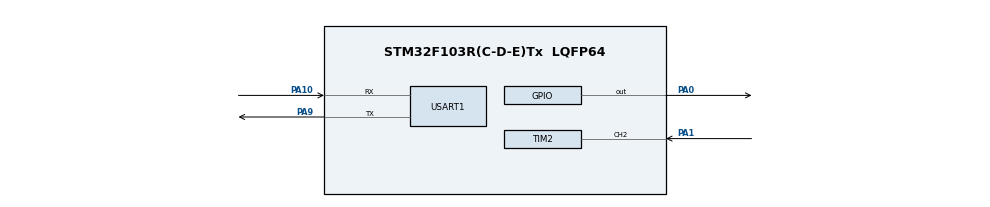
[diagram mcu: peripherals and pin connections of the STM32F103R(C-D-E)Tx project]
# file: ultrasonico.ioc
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Mcu.Family=STM32F1
Mcu.Name=STM32F103R(C-D-E)Tx
Mcu.Package=LQFP64
NVIC.PriorityGroup=NVIC_PRIORITYGROUP_4
PA0-WKUP.Signal=GPIO_Output
PA1.Signal=S_TIM2_CH2
PA10.Mode=Asynchronous
PA10.Signal=USART1_RX
PA9.Mode=Asynchronous
PA9.Signal=USART1_TX
ProjectManager.HeapSize=0x200
ProjectManager.StackSize=0x400
ProjectManager.TargetToolchain=STM32CubeIDE
RCC.APB1Freq_Value=8000000
RCC.APB2Freq_Value=8000000
SH.S_TIM2_CH2.0=TIM2_CH2,Input_Capture2_from_TI2
TIM2.Channel-Input_Capture2_from_TI2=TIM_CHANNEL_2
TIM2.ICPrescaler-Input_Capture2_from_TI2=TIM_ICPSC_DIV1
TIM2.Prescaler=71
USART1.VirtualMode=VM_ASYNC
VP_SYS_VS_ND.Mode=No_Debug
board=custom

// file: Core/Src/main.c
/* USER CODE BEGIN Header */
/**
  ******************************************************************************
  * @file           : main.c
  * @brief          : Main program body
  ******************************************************************************
  */
/* USER CODE END Header */

#include "main.h"

/* USER CODE BEGIN Includes */
#include "ultrasonic.h"
#include <stdio.h>
/* USER CODE END Includes */

UART_HandleTypeDef huart1;
TIM_HandleTypeDef htim2;

/* USER CODE BEGIN PV */
uint32_t distancia_cm = 0;
/* USER CODE END PV */

void SystemClock_Config(void);
static void MX_GPIO_Init(void);
static void MX_TIM2_Init(void);
static void MX_USART1_UART_Init(void);

/* USER CODE BEGIN 0 */
int __io_putchar(int ch)
{
    HAL_UART_Transmit(&huart1, (uint8_t *)&ch, 1, HAL_MAX_DELAY);
    return ch;
}
/* USER CODE END 0 */

int main(void)
{
    HAL_Init();
    SystemClock_Config();
    MX_GPIO_Init();
    MX_TIM2_Init();
    MX_USART1_UART_Init();

    /* USER CODE BEGIN 2 */
    HAL_TIM_Base_Start(&htim2, TIM_CHANNEL_2);
    /* USER CODE END 2 */

    while (1)
    {
        /* USER CODE BEGIN 3 */
        distancia_cm = Ultrasonic_GetDistance_cm();
        printf("Distancia: %lu cm\r\n", distancia_cm);
        HAL_Delay(200);
        /* USER CODE END 3 */
    }
}

void SystemClock_Config(void)
{
    RCC_OscInitTypeDef RCC_OscInitStruct = {0};
    RCC_ClkInitTypeDef RCC_ClkInitStruct = {0};

    RCC_OscInitStruct.OscillatorType = RCC_OSCILLATORTYPE_HSI;
    RCC_OscInitStruct.HSIState = RCC_HSI_ON;
    RCC_OscInitStruct.HSICalibrationValue = RCC_HSICALIBRATION_DEFAULT;
    RCC_OscInitStruct.PLL.PLLState = RCC_PLL_NONE;
    if (HAL_RCC_OscConfig(&RCC_OscInitStruct) != HAL_OK)
        Error_Handler();

    RCC_ClkInitStruct.ClockType = RCC_CLOCKTYPE_HCLK | RCC_CLOCKTYPE_SYSCLK
                                | RCC_CLOCKTYPE_PCLK1 | RCC_CLOCKTYPE_PCLK2;
    RCC_ClkInitStruct.SYSCLKSource = RCC_SYSCLKSOURCE_HSI;
    RCC_ClkInitStruct.AHBCLKDivider = RCC_SYSCLK_DIV1;
    RCC_ClkInitStruct.APB1CLKDivider = RCC_HCLK_DIV1;
    RCC_ClkInitStruct.APB2CLKDivider = RCC_HCLK_DIV1;

    if (HAL_RCC_ClockConfig(&RCC_ClkInitStruct, FLASH_LATENCY_0) != HAL_OK)
        Error_Handler();
}

static void MX_USART1_UART_Init(void)
{
    huart1.Instance          = USART1;
    huart1.Init.BaudRate     = 115200;
    huart1.Init.WordLength   = UART_WORDLENGTH_8B;
    huart1.Init.StopBits     = UART_STOPBITS_1;
    huart1.Init.Parity       = UART_PARITY_NONE;
    huart1.Init.Mode         = UART_MODE_TX_RX;
    huart1.Init.HwFlowCtl    = UART_HWCONTROL_NONE;
    huart1.Init.OverSampling = UART_OVERSAMPLING_16;
    if (HAL_UART_Init(&huart1) != HAL_OK)
        Error_Handler();
}

static void MX_TIM2_Init(void)
{
    TIM_MasterConfigTypeDef sMasterConfig = {0};
    TIM_IC_InitTypeDef sConfigIC = {0};

    htim2.Instance = TIM2;
    htim2.Init.Prescaler = 7;           /* HSI 8 MHz / 8 = 1 MHz → 1 tick = 1 µs */
    htim2.Init.CounterMode = TIM_COUNTERMODE_UP;
    htim2.Init.Period = 65535;
    htim2.Init.ClockDivision = TIM_CLOCKDIVISION_DIV1;
    htim2.Init.AutoReloadPreload = TIM_AUTORELOAD_PRELOAD_DISABLE;
    if (HAL_TIM_IC_Init(&htim2) != HAL_OK)
        Error_Handler();

    sMasterConfig.MasterOutputTrigger = TIM_TRGO_RESET;
    sMasterConfig.MasterSlaveMode = TIM_MASTERSLAVEMODE_DISABLE;
    if (HAL_TIMEx_MasterConfigSynchronization(&htim2, &sMasterConfig) != HAL_OK)
        Error_Handler();

    sConfigIC.ICPolarity  = TIM_INPUTCHANNELPOLARITY_RISING;
    sConfigIC.ICSelection = TIM_ICSELECTION_DIRECTTI;
    sConfigIC.ICPrescaler = TIM_ICPSC_DIV1;
    sConfigIC.ICFilter    = 0;
    if (HAL_TIM_IC_ConfigChannel(&htim2, &sConfigIC, TIM_CHANNEL_2) != HAL_OK)
        Error_Handler();
}

static void MX_GPIO_Init(void)
{
    GPIO_InitTypeDef GPIO_InitStruct = {0};

    __HAL_RCC_GPIOA_CLK_ENABLE();

    HAL_GPIO_WritePin(GPIOA, GPIO_PIN_0, GPIO_PIN_RESET);

    /* PA0 → TRIG (salida) */
    GPIO_InitStruct.Pin   = GPIO_PIN_0;
    GPIO_InitStruct.Mode  = GPIO_MODE_OUTPUT_PP;
    GPIO_InitStruct.Pull  = GPIO_NOPULL;
    GPIO_InitStruct.Speed = GPIO_SPEED_FREQ_LOW;
    HAL_GPIO_Init(GPIOA, &GPIO_InitStruct);

    /* PA9 → USART1_TX */
    GPIO_InitStruct.Pin   = GPIO_PIN_9;
    GPIO_InitStruct.Mode  = GPIO_MODE_AF_PP;
    GPIO_InitStruct.Speed = GPIO_SPEED_FREQ_HIGH;
    HAL_GPIO_Init(GPIOA, &GPIO_InitStruct);

    /* PA10 → USART1_RX */
    GPIO_InitStruct.Pin  = GPIO_PIN_10;
    GPIO_InitStruct.Mode = GPIO_MODE_INPUT;
    GPIO_InitStruct.Pull = GPIO_NOPULL;
    HAL_GPIO_Init(GPIOA, &GPIO_InitStruct);
}

/* USER CODE BEGIN 4 */
void HAL_TIM_IC_CaptureCallback(TIM_HandleTypeDef *htim)
{
    Ultrasonic_CaptureCallback(htim);
}

void HAL_TIM_PeriodElapsedCallback(TIM_HandleTypeDef *htim)
{
    Ultrasonic_OverflowCallback(htim);
}
/* USER CODE END 4 */

void Error_Handler(void)
{
    __disable_irq();
    while (1) {}
}
